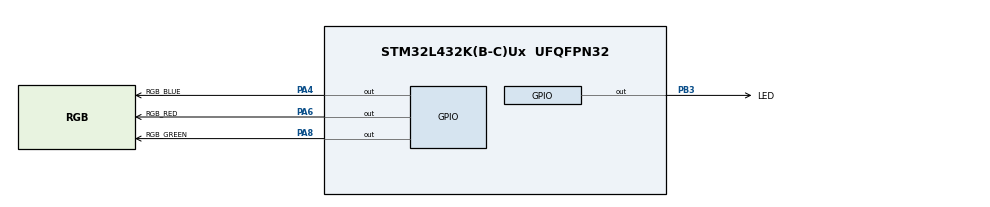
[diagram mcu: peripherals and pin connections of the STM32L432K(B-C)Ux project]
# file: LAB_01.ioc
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Mcu.Family=STM32L4
Mcu.Name=STM32L432K(B-C)Ux
Mcu.Package=UFQFPN32
NVIC.PriorityGroup=NVIC_PRIORITYGROUP_4
PA13\ (JTMS-SWDIO).Mode=Serial_Wire
PA13\ (JTMS-SWDIO).Signal=SYS_JTMS-SWDIO
PA14\ (JTCK-SWCLK).Mode=Serial_Wire
PA14\ (JTCK-SWCLK).Signal=SYS_JTCK-SWCLK
PA4.GPIO_Label=RGB_BLUE
PA4.Signal=GPIO_Output
PA6.GPIO_Label=RGB_RED
PA6.Signal=GPIO_Output
PA8.GPIO_Label=RGB_GREEN
PA8.Signal=GPIO_Output
PB3\ (JTDO-TRACESWO).GPIO_Label=LED
PB3\ (JTDO-TRACESWO).Signal=GPIO_Output
ProjectManager.HeapSize=0x200
ProjectManager.StackSize=0x400
ProjectManager.TargetToolchain=STM32CubeIDE
RCC.HSE_VALUE=8000000
RCC.HSI48_VALUE=48000000
RCC.HSI_VALUE=16000000
RCC.LSE_VALUE=32768
RCC.MSI_VALUE=4000000
RCC.VCOOutputFreq_Value=32000000
board=custom

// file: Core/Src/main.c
/* USER CODE BEGIN Header */
/**
  ******************************************************************************
  * @file           : main.c
  * @brief          : Main program body
  ******************************************************************************
  * @attention
  *
  * <h2><center>&copy; Copyright (c) 2021 STMicroelectronics.
  * All rights reserved.</center></h2>
  *
  * This software component is licensed by ST under BSD 3-Clause license,
  * the "License"; You may not use this file except in compliance with the
  * License. You may obtain a copy of the License at:
  *                        opensource.org/licenses/BSD-3-Clause
  *
  ******************************************************************************
  */
/* USER CODE END Header */
#include "main.h"

void SystemClock_Config(void);
static void MX_GPIO_Init(void);

int main(void)
{
  /* USER CODE BEGIN 1 */
  int counter = 0;
  /* USER CODE END 1 */

  /* MCU Configuration--------------------------------------------------------*/

  /* Reset of all peripherals, Initializes the Flash interface and the Systick. */
  HAL_Init();

  /* Configure the system clock */
  SystemClock_Config();

  /* Initialize all configured peripherals */
  MX_GPIO_Init();
  /* USER CODE BEGIN 2 */

  // HAL_GPIO_WritePin (Port, Pin, State)
  // example: HAL_GPIO_WritePin(LED_GPIO_Port, LED_Pin, 1);
  // GPIO_PIN_SET or GPIO_PIN_RESET can be used too, for better abstraction
  HAL_GPIO_WritePin(LED_GPIO_Port, LED_Pin, GPIO_PIN_RESET);
  HAL_GPIO_WritePin(RGB_RED_GPIO_Port, RGB_RED_Pin, GPIO_PIN_RESET);
  HAL_GPIO_WritePin(RGB_GREEN_GPIO_Port, RGB_GREEN_Pin, GPIO_PIN_RESET);
  HAL_GPIO_WritePin(RGB_BLUE_GPIO_Port, RGB_BLUE_Pin, GPIO_PIN_RESET);
  /* USER CODE END 2 */

  /* Infinite loop */
  /* USER CODE BEGIN WHILE */
  while (1)
  {
	  //HAL_Delay(delay in milliseconds)
	  //HAL_GPIO_TogglePin(Port, Pin)
	  HAL_Delay(500);
	  HAL_GPIO_TogglePin(LED_GPIO_Port, LED_Pin);

	  // counter 0...7
	  // Red counter & 0x01
	  // Green counter & 0x02
	  // Blue counter & 0x04
	  counter++;
	  if(counter > 7) {
		  counter = 0;
	  }
	  HAL_GPIO_WritePin(RGB_RED_GPIO_Port, RGB_RED_Pin, counter&0x01);
	  HAL_GPIO_WritePin(RGB_GREEN_GPIO_Port, RGB_GREEN_Pin, counter&0x02);
	  HAL_GPIO_WritePin(RGB_BLUE_GPIO_Port, RGB_BLUE_Pin, counter&0x04);
    /* USER CODE END WHILE */

  }
}

void SystemClock_Config(void)
{
  RCC_OscInitTypeDef RCC_OscInitStruct = {0};
  RCC_ClkInitTypeDef RCC_ClkInitStruct = {0};

  /** Configure the main internal regulator output voltage
  */
  if (HAL_PWREx_ControlVoltageScaling(PWR_REGULATOR_VOLTAGE_SCALE1) != HAL_OK)
  {
    Error_Handler();
  }
  /** Initializes the RCC Oscillators according to the specified parameters
  * in the RCC_OscInitTypeDef structure.
  */
  RCC_OscInitStruct.OscillatorType = RCC_OSCILLATORTYPE_MSI;
  RCC_OscInitStruct.MSIState = RCC_MSI_ON;
  RCC_OscInitStruct.MSICalibrationValue = 0;
  RCC_OscInitStruct.MSIClockRange = RCC_MSIRANGE_6;
  RCC_OscInitStruct.PLL.PLLState = RCC_PLL_NONE;
  if (HAL_RCC_OscConfig(&RCC_OscInitStruct) != HAL_OK)
  {
    Error_Handler();
  }
  /** Initializes the CPU, AHB and APB buses clocks
  */
  RCC_ClkInitStruct.ClockType = RCC_CLOCKTYPE_HCLK|RCC_CLOCKTYPE_SYSCLK
                              |RCC_CLOCKTYPE_PCLK1|RCC_CLOCKTYPE_PCLK2;
  RCC_ClkInitStruct.SYSCLKSource = RCC_SYSCLKSOURCE_MSI;
  RCC_ClkInitStruct.AHBCLKDivider = RCC_SYSCLK_DIV1;
  RCC_ClkInitStruct.APB1CLKDivider = RCC_HCLK_DIV1;
  RCC_ClkInitStruct.APB2CLKDivider = RCC_HCLK_DIV1;

  if (HAL_RCC_ClockConfig(&RCC_ClkInitStruct, FLASH_LATENCY_0) != HAL_OK)
  {
    Error_Handler();
  }
}

static void MX_GPIO_Init(void)
{
  GPIO_InitTypeDef GPIO_InitStruct = {0};

  /* GPIO Ports Clock Enable */
  __HAL_RCC_GPIOA_CLK_ENABLE();
  __HAL_RCC_GPIOB_CLK_ENABLE();

  /*Configure GPIO pin Output Level */
  HAL_GPIO_WritePin(GPIOA, RGB_BLUE_Pin|RGB_RED_Pin|RGB_GREEN_Pin, GPIO_PIN_RESET);

  /*Configure GPIO pin Output Level */
  HAL_GPIO_WritePin(LED_GPIO_Port, LED_Pin, GPIO_PIN_RESET);

  /*Configure GPIO pins : RGB_BLUE_Pin RGB_RED_Pin RGB_GREEN_Pin */
  GPIO_InitStruct.Pin = RGB_BLUE_Pin|RGB_RED_Pin|RGB_GREEN_Pin;
  GPIO_InitStruct.Mode = GPIO_MODE_OUTPUT_PP;
  GPIO_InitStruct.Pull = GPIO_NOPULL;
  GPIO_InitStruct.Speed = GPIO_SPEED_FREQ_LOW;
  HAL_GPIO_Init(GPIOA, &GPIO_InitStruct);

  /*Configure GPIO pin : LED_Pin */
  GPIO_InitStruct.Pin = LED_Pin;
  GPIO_InitStruct.Mode = GPIO_MODE_OUTPUT_PP;
  GPIO_InitStruct.Pull = GPIO_NOPULL;
  GPIO_InitStruct.Speed = GPIO_SPEED_FREQ_LOW;
  HAL_GPIO_Init(LED_GPIO_Port, &GPIO_InitStruct);

}

void Error_Handler(void)
{
  __disable_irq();
  while (1)
  {
  }
}

/************************ (C) COPYRIGHT STMicroelectronics *****END OF FILE****/
